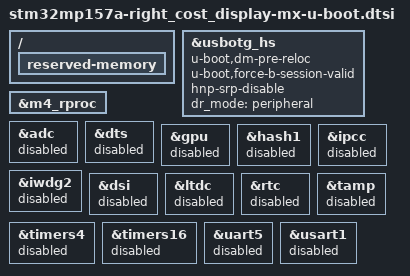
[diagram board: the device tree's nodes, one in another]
/* SPDX-License-Identifier: GPL-2.0+ OR BSD-3-Clause*/
/*
 * Copyright (C) 2023, STMicroelectronics - All Rights Reserved
 * Author: STM32CubeMX code generation for STMicroelectronics.
 */

/* For more information on Device Tree configuration, please refer to
 * https://wiki.st.com/stm32mpu/wiki/Category:Device_tree_configuration
 */

#include "stm32mp15-u-boot.dtsi"

/* USER CODE BEGIN includes */
/* USER CODE END includes */

/ {

	/* USER CODE BEGIN root */
	/* We are deleting reserved memory as it increased file read times by 2x (275ms) */
	/* The devices using this memory (m4 & gpu) are not needed in u-boot. */
	reserved-memory {
		/delete-node/mcuram2@10000000;
		/delete-node/vdev0vring0@10040000;
		/delete-node/vdev0vring1@10041000;
		/delete-node/vdev0buffer@10042000;
		/delete-node/mcuram@30000000;
		/delete-node/retram@38000000;
		/delete-node/gpu@c1000000;
	};
	/* USER CODE END root */

}; /*root*/

/* USER CODE BEGIN addons */
&usbotg_hs{
	u-boot,dm-pre-reloc;
	u-boot,force-b-session-valid;
	hnp-srp-disable;
	dr_mode = "peripheral";
	/delete-property/phys;
};

&m4_rproc{
	/* Deleted because we do not reserve the sram for the m4 in u-boot */
	/delete-property/memory-region;
};

&adc{
	status = "disabled";
};

&dts{
	status = "disabled";
};

&gpu{
	/* Deleted because we do not reserve the memory in u-boot */
	/delete-property/contiguous-area;
	status = "disabled";
};

&hash1{
	status = "disabled";
};

&ipcc{
	status = "disabled";
};

&iwdg2{
	status = "disabled";
};

&dsi {
	status = "disabled";
};

&ltdc {
	status = "disabled";
};

&rtc{
	status = "disabled";
};

&tamp{
	status = "disabled";
};

&timers4{
	status = "disabled";
};

&timers16{
	status = "disabled";
};

&uart5{
	status = "disabled";
};

&usart1{
	status = "disabled";
};
/* USER CODE END addons */

